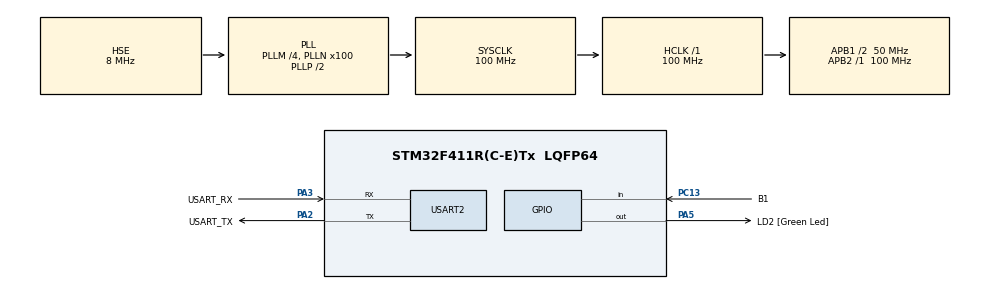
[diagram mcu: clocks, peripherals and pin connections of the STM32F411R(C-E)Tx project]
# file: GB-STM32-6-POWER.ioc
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Mcu.Family=STM32F4
Mcu.Name=STM32F411R(C-E)Tx
Mcu.Package=LQFP64
NVIC.PriorityGroup=NVIC_PRIORITYGROUP_0
NVIC.TIM1_UP_TIM10_IRQn=true\:0\:0\:false\:false\:true\:true\:true
PA13.GPIO_Label=TMS
PA13.Mode=Serial_Wire
PA13.Signal=SYS_JTMS-SWDIO
PA14.GPIO_Label=TCK
PA14.Mode=Serial_Wire
PA14.Signal=SYS_JTCK-SWCLK
PA2.GPIO_Label=USART_TX
PA2.Mode=Asynchronous
PA2.Signal=USART2_TX
PA3.GPIO_Label=USART_RX
PA3.Mode=Asynchronous
PA3.Signal=USART2_RX
PA5.GPIO_Label=LD2 [Green Led]
PA5.Signal=GPIO_Output
PB3.GPIO_Label=SWO
PB3.Signal=SYS_JTDO-SWO
PC13-ANTI_TAMP.GPIO_Label=B1
PC13-ANTI_TAMP.GPIO_PuPd=GPIO_PULLUP
PC13-ANTI_TAMP.Signal=GPIO_Input
PC14-OSC32_IN.Mode=LSE-External-Oscillator
PC14-OSC32_IN.Signal=RCC_OSC32_IN
PC15-OSC32_OUT.Mode=LSE-External-Oscillator
PC15-OSC32_OUT.Signal=RCC_OSC32_OUT
PH0\ -\ OSC_IN.Mode=HSE-External-Clock-Source
PH0\ -\ OSC_IN.Signal=RCC_OSC_IN
PH1\ -\ OSC_OUT.Mode=HSE-External-Clock-Source
PH1\ -\ OSC_OUT.Signal=RCC_OSC_OUT
ProjectManager.HeapSize=0x200
ProjectManager.StackSize=0x400
ProjectManager.TargetToolchain=STM32CubeIDE
RCC.48MHZClocksFreq_Value=50000000
RCC.AHBFreq_Value=100000000
RCC.APB1CLKDivider=RCC_HCLK_DIV2
RCC.APB1Freq_Value=50000000
RCC.APB1TimFreq_Value=100000000
RCC.APB2Freq_Value=100000000
RCC.APB2TimFreq_Value=100000000
RCC.CortexFreq_Value=100000000
RCC.EnbaleCSS=true
RCC.FLatency-AdvancedSettings=FLASH_LATENCY_3
RCC.HCLKFreq_Value=100000000
RCC.HSE_VALUE=8000000
RCC.HSI_VALUE=16000000
RCC.PLLM=4
RCC.PLLN=100
RCC.PLLSourceVirtual=RCC_PLLSOURCE_HSE
RCC.SYSCLKFreq_VALUE=100000000
RCC.SYSCLKSource=RCC_SYSCLKSOURCE_PLLCLK
RCC.VCOOutputFreq_Value=200000000
TIM1.Channel-Output\ Compare1\ No\ Output=TIM_CHANNEL_1
TIM1.Period=9999
TIM1.Prescaler=999
USART2.VirtualMode=VM_ASYNC
VP_TIM1_VS_ClockSourceINT.Mode=Internal
VP_TIM1_VS_no_output1.Mode=Output Compare1 No Output
board=NUCLEO-F411RE

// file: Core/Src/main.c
/* USER CODE BEGIN Header */
/**
 ******************************************************************************
 * @file           : main.c
 * @brief          : Main program body
 ******************************************************************************
 * @attention
 *
 * <h2><center>&copy; Copyright (c) 2021 STMicroelectronics.
 * All rights reserved.</center></h2>
 *
 * This software component is licensed by ST under BSD 3-Clause license,
 * the "License"; You may not use this file except in compliance with the
 * License. You may obtain a copy of the License at:
 *                        opensource.org/licenses/BSD-3-Clause
 *
 ******************************************************************************
 */
/* USER CODE END Header */
#include "main.h"
#include "tim.h"
#include "usart.h"
#include "gpio.h"

void SystemClock_Config(void);

/* USER CODE BEGIN 0 */
void HAL_TIM_PeriodElapsedCallback(TIM_HandleTypeDef *htim)
{
        if(htim->Instance == TIM1) //check if the interrupt comes from TIM1
        {
                HAL_ResumeTick();
        }
}
/* USER CODE END 0 */

int main(void)
{

  /* MCU Configuration--------------------------------------------------------*/

  /* Reset of all peripherals, Initializes the Flash interface and the Systick. */
  HAL_Init();

  /* Configure the system clock */
  SystemClock_Config();

  /* Initialize all configured peripherals */
  MX_GPIO_Init();
  MX_USART2_UART_Init();
  MX_TIM1_Init();
  /* USER CODE BEGIN 2 */
  HAL_TIM_Base_Start_IT(&htim1);
  /* USER CODE END 2 */

  /* Infinite loop */
	while (1) {

    /* USER CODE BEGIN 3 */
        HAL_GPIO_TogglePin(LD2_GPIO_Port, LD2_Pin);
        HAL_Delay(500);
        HAL_GPIO_TogglePin(LD2_GPIO_Port, LD2_Pin);
        HAL_Delay(500);
        HAL_GPIO_TogglePin(LD2_GPIO_Port, LD2_Pin);
        HAL_Delay(500);
        HAL_GPIO_TogglePin(LD2_GPIO_Port, LD2_Pin);
        HAL_Delay(500);
		HAL_SuspendTick();
		HAL_PWR_EnterSLEEPMode(PWR_LOWPOWERREGULATOR_ON, PWR_SLEEPENTRY_WFI);
	}
  /* USER CODE END 3 */
}

void SystemClock_Config(void)
{
  RCC_OscInitTypeDef RCC_OscInitStruct = {0};
  RCC_ClkInitTypeDef RCC_ClkInitStruct = {0};

  /** Configure the main internal regulator output voltage
  */
  __HAL_RCC_PWR_CLK_ENABLE();
  __HAL_PWR_VOLTAGESCALING_CONFIG(PWR_REGULATOR_VOLTAGE_SCALE1);
  /** Initializes the RCC Oscillators according to the specified parameters
  * in the RCC_OscInitTypeDef structure.
  */
  RCC_OscInitStruct.OscillatorType = RCC_OSCILLATORTYPE_HSE;
  RCC_OscInitStruct.HSEState = RCC_HSE_BYPASS;
  RCC_OscInitStruct.PLL.PLLState = RCC_PLL_ON;
  RCC_OscInitStruct.PLL.PLLSource = RCC_PLLSOURCE_HSE;
  RCC_OscInitStruct.PLL.PLLM = 4;
  RCC_OscInitStruct.PLL.PLLN = 100;
  RCC_OscInitStruct.PLL.PLLP = RCC_PLLP_DIV2;
  RCC_OscInitStruct.PLL.PLLQ = 4;
  if (HAL_RCC_OscConfig(&RCC_OscInitStruct) != HAL_OK)
  {
    Error_Handler();
  }
  /** Initializes the CPU, AHB and APB buses clocks
  */
  RCC_ClkInitStruct.ClockType = RCC_CLOCKTYPE_HCLK|RCC_CLOCKTYPE_SYSCLK
                              |RCC_CLOCKTYPE_PCLK1|RCC_CLOCKTYPE_PCLK2;
  RCC_ClkInitStruct.SYSCLKSource = RCC_SYSCLKSOURCE_PLLCLK;
  RCC_ClkInitStruct.AHBCLKDivider = RCC_SYSCLK_DIV1;
  RCC_ClkInitStruct.APB1CLKDivider = RCC_HCLK_DIV2;
  RCC_ClkInitStruct.APB2CLKDivider = RCC_HCLK_DIV1;

  if (HAL_RCC_ClockConfig(&RCC_ClkInitStruct, FLASH_LATENCY_3) != HAL_OK)
  {
    Error_Handler();
  }
  /** Enables the Clock Security System
  */
  HAL_RCC_EnableCSS();
}

void Error_Handler(void)
{
	__disable_irq();
	while (1) {
	}
}

/************************ (C) COPYRIGHT STMicroelectronics *****END OF FILE****/
